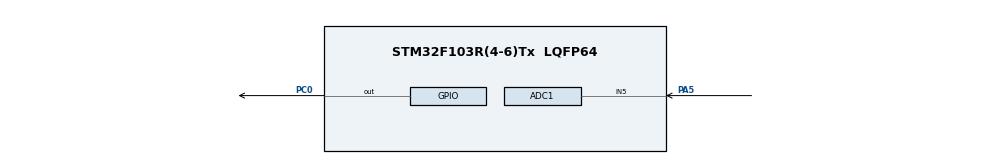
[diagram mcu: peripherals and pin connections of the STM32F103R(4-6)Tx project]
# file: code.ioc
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Mcu.Family=STM32F1
RCC.APB2Freq_Value=8000000
PC0.GPIO_ModeDefaultOutputPP=GPIO_MODE_OUTPUT_PP
Mcu.Name=STM32F103R(4-6)Tx
PC0.Signal=GPIO_Output
VP_SYS_VS_ND.Mode=No_Debug
Mcu.Package=LQFP64
ADC1.master=1
ProjectManager.StackSize=0x400
ADC1.Rank-3\#ChannelRegularConversion=1
ADC1.SamplingTime-3\#ChannelRegularConversion=ADC_SAMPLETIME_1CYCLE_5
ProjectManager.HeapSize=0x200
ProjectManager.TargetToolchain=Makefile
SH.ADCx_IN5.0=ADC1_IN5,IN5
NVIC.PriorityGroup=NVIC_PRIORITYGROUP_4
ADC1.NbrOfConversionFlag=1
ADC1.Channel-3\#ChannelRegularConversion=ADC_CHANNEL_5
PC0.GPIO_PuPd=GPIO_PULLUP
RCC.APB1Freq_Value=8000000
PC0.PinState=GPIO_PIN_RESET
PA5.Signal=ADCx_IN5
board=custom

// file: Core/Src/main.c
/* USER CODE BEGIN Header */
/**
 ******************************************************************************
 * @file           : main.c
 * @brief          : Main program body
 ******************************************************************************
 * @attention
 *
 * <h2><center>&copy; Copyright (c) 2021 STMicroelectronics.
 * All rights reserved.</center></h2>
 *
 * This software component is licensed by ST under BSD 3-Clause license,
 * the "License"; You may not use this file except in compliance with the
 * License. You may obtain a copy of the License at:
 *                        opensource.org/licenses/BSD-3-Clause
 *
 ******************************************************************************
 */
/* USER CODE END Header */
#include "main.h"
#include "adc.h"
#include "gpio.h"

/* USER CODE BEGIN Includes */
#include <stdio.h>
#include <string.h>
/* USER CODE END Includes */

void SystemClock_Config(void);

int main(void)
{
  /* USER CODE BEGIN 1 */
	/*
	 * Cilj primera jeste inicijalizacija analogno digitalnog konvertora i to
	 * njegovog kanala 5 koji je mapiran na opstenamenski pin PA5.
	 * Nakon inicijalizacije, u beskonacnoj petlji ocitavacemo analognu vrednost
	 * napona sa ulaza, na koji je povezan potenciometar, i u zavisnosti od
	 * njegovog intenziteta kontrolisacemo LE Diodu, povezanu na opstenamenski pin PC0.
	 */
	uint16_t raw;  //ovde se smesta digitalna vrednost nakon konverzije
  /* USER CODE END 1 */

  /* MCU Configuration--------------------------------------------------------*/

  /* Reset of all peripherals, Initializes the Flash interface and the Systick. */
  HAL_Init();

  /* Configure the system clock */
  SystemClock_Config();

  /* Initialize all configured peripherals */
  MX_GPIO_Init();
  MX_ADC1_Init();
  /* USER CODE BEGIN 2 */

	// HAL_ADC_Start(&hadc1);
	//HAL_ADC_PollForConversion(&hadc1, HAL_MAX_DELAY);
  /* USER CODE END 2 */

  /* Infinite loop */
  /* USER CODE BEGIN WHILE */
	/*
	 * Prvo cemo pozivom funkcije HAL_ADC_Start pokrenuti AD konvertor, nakon
	 * cega moramo sacekati odredjeni broj taktova da se konverzija zavrsi. Ovo
	 * se postize blokirajucim pozivom funkcije HAL_ADC_PollForConversion.
	 * Nakon toga mozemo ocitati konvertovanu vrednost iz Data Registra ADC
	 * periferije ili pozivom funkcije HAL_ADC_GetValue.
	 * S obzirom da je rezolucija AD konvertora 12 bita, dobijacemo digitalne
	 * vrednosti u opsegu [0, 4095] koje reprezentuju napon intenziteta
	 * (0, 3.3)V. Ako intenzitet napona predje 50% maksimalne vrednosti
	 * ukljucicemo LE Diodu dok je u suprotnom dioda iskljucena.
	 */
	while (1) {
		HAL_ADC_Start(&hadc1);
		HAL_ADC_PollForConversion(&hadc1, HAL_MAX_DELAY);
		// raw = ADC1->DR;
		raw = HAL_ADC_GetValue(&hadc1);

		if (raw > 2047) {           //12 bit-a, digitalne vrednosti od 0 do 4095
			HAL_GPIO_WritePin(GPIOC, GPIO_PIN_0, GPIO_PIN_SET);
		} else {
			HAL_GPIO_WritePin(GPIOC, GPIO_PIN_0, GPIO_PIN_RESET);
		}
		HAL_Delay(200);
    /* USER CODE END WHILE */

	}
}

void SystemClock_Config(void)
{
  RCC_OscInitTypeDef RCC_OscInitStruct = {0};
  RCC_ClkInitTypeDef RCC_ClkInitStruct = {0};
  RCC_PeriphCLKInitTypeDef PeriphClkInit = {0};

  /** Initializes the RCC Oscillators according to the specified parameters
  * in the RCC_OscInitTypeDef structure.
  */
  RCC_OscInitStruct.OscillatorType = RCC_OSCILLATORTYPE_HSI;
  RCC_OscInitStruct.HSIState = RCC_HSI_ON;
  RCC_OscInitStruct.HSICalibrationValue = RCC_HSICALIBRATION_DEFAULT;
  RCC_OscInitStruct.PLL.PLLState = RCC_PLL_NONE;
  if (HAL_RCC_OscConfig(&RCC_OscInitStruct) != HAL_OK)
  {
    Error_Handler();
  }
  /** Initializes the CPU, AHB and APB buses clocks
  */
  RCC_ClkInitStruct.ClockType = RCC_CLOCKTYPE_HCLK|RCC_CLOCKTYPE_SYSCLK
                              |RCC_CLOCKTYPE_PCLK1|RCC_CLOCKTYPE_PCLK2;
  RCC_ClkInitStruct.SYSCLKSource = RCC_SYSCLKSOURCE_HSI;
  RCC_ClkInitStruct.AHBCLKDivider = RCC_SYSCLK_DIV1;
  RCC_ClkInitStruct.APB1CLKDivider = RCC_HCLK_DIV1;
  RCC_ClkInitStruct.APB2CLKDivider = RCC_HCLK_DIV1;

  if (HAL_RCC_ClockConfig(&RCC_ClkInitStruct, FLASH_LATENCY_0) != HAL_OK)
  {
    Error_Handler();
  }
  PeriphClkInit.PeriphClockSelection = RCC_PERIPHCLK_ADC;
  PeriphClkInit.AdcClockSelection = RCC_ADCPCLK2_DIV2;
  if (HAL_RCCEx_PeriphCLKConfig(&PeriphClkInit) != HAL_OK)
  {
    Error_Handler();
  }
}

void Error_Handler(void)
{
	__disable_irq();
	while (1) {
	}
}

/************************ (C) COPYRIGHT STMicroelectronics *****END OF FILE****/
